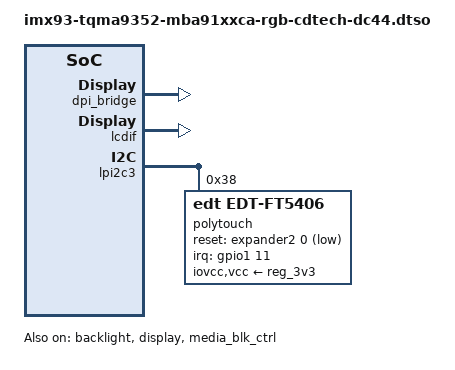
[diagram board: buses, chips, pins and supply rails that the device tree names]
// SPDX-License-Identifier: (GPL-2.0-or-later OR MIT)
/*
 * Copyright (c) 2023-2026 TQ-Systems GmbH <linux@ew.tq-group.com>,
 * D-82229 Seefeld, Germany.
 * Author: Alexander Stein
 */

#include <dt-bindings/clock/imx93-clock.h>
#include <dt-bindings/gpio/gpio.h>
#include <dt-bindings/interrupt-controller/irq.h>

/dts-v1/;
/plugin/;

&backlight {
	status = "okay";
};

&display {
	compatible = "cdtech,s070swv29hg-dc44";
	status = "okay";
};

&dpi_bridge {
	pinctrl-names = "default";
	pinctrl-0 = <&pinctrl_rgbdisp>;
	status = "okay";
};

&dpi_to_panel {
	remote-endpoint = <&panel_in>;
};

&lcdif {
	assigned-clocks = <&clk IMX93_CLK_VIDEO_PLL>;
	assigned-clock-rates = <333333333>;
	status = "okay";
};

&lpi2c3 {
	#address-cells = <1>;
	#size-cells = <0>;

	polytouch: touchscreen@38 {
		compatible = "edt,edt-ft5406";
		reg = <0x38>;
		pinctrl-names = "default";
		pinctrl-0 = <&pinctrl_touch>;
		interrupt-parent = <&gpio1>;
		interrupts = <11 IRQ_TYPE_EDGE_FALLING>;
		reset-gpios = <&expander2 0 GPIO_ACTIVE_LOW>;
		iovcc-supply = <&reg_3v3>;
		vcc-supply = <&reg_3v3>;
		gain = <20>;
		touchscreen-size-x = <800>;
		touchscreen-size-y = <480>;
	};
};

&media_blk_ctrl {
	status = "okay";
};

&panel_in {
	remote-endpoint = <&dpi_to_panel>;
};
